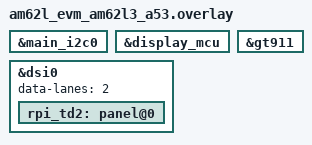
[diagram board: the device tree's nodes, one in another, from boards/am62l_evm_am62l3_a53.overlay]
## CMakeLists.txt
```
# SPDX-FileCopyrightText: 2026 Texas Instruments Incorporated
# SPDX-License-Identifier: LicenseRef-TI-TFL

cmake_minimum_required(VERSION 3.20.0)

find_package(Zephyr REQUIRED HINTS $ENV{ZEPHYR_BASE})
project(ti_smart_home)

set(UI_DIR ${CMAKE_CURRENT_SOURCE_DIR}/ui)

include(${UI_DIR}/file_list_gen.cmake)
include(${UI_DIR}/user_config.cmake)

target_sources(app PRIVATE
    src/main.c
    ${LV_EDITOR_PROJECT_SOURCES}
)

target_include_directories(app PRIVATE ${UI_DIR})

target_compile_definitions(app PRIVATE LV_LVGL_H_INCLUDE_SIMPLE)
```

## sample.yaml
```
sample:
  name: TI Smart Home LVGL UI
  description: >
    Smart Home LVGL UI with Raspberry Pi Touch Display 2 (7", ILI9881C MIPI-DSI
    panel) and GT911 capacitive touch controller.
tests:
  application.ti_smart_home:
    tags:
      - lvgl
      - display
      - gui
    harness: none
    platform_allow:
      - am62l_evm/am62l3/a53
```

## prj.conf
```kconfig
# SPDX-FileCopyrightText: 2026 Texas Instruments Incorporated
# SPDX-License-Identifier: LicenseRef-TI-TFL

CONFIG_DISPLAY=y
CONFIG_LVGL=y
CONFIG_INPUT=y

# ARGB8888 pixel format
CONFIG_LV_COLOR_DEPTH_32=y

# Widgets and features used by the ti-smart-home UI
CONFIG_LV_USE_BAR=y
CONFIG_LV_USE_BUTTON=y
CONFIG_LV_USE_CHART=y
CONFIG_LV_USE_CHECKBOX=y
CONFIG_LV_USE_IMAGE=y
CONFIG_LV_USE_LABEL=y
CONFIG_LV_USE_SLIDER=y
CONFIG_LV_USE_SWITCH=y
CONFIG_LV_USE_OBSERVER=y
CONFIG_LV_USE_OBJ_NAME=y
```

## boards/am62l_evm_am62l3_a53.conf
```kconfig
# SPDX-FileCopyrightText: 2026 Texas Instruments Incorporated
# SPDX-License-Identifier: LicenseRef-TI-TFL

CONFIG_MAIN_STACK_SIZE=12288
CONFIG_LV_Z_MEM_POOL_SIZE=262144
CONFIG_LV_Z_BUFFER_ALLOC_STATIC=y
CONFIG_LV_Z_DOUBLE_VDB=y
CONFIG_LV_Z_FLUSH_THREAD=y
CONFIG_LV_Z_RUN_LVGL_ON_WORKQUEUE=y
CONFIG_LV_Z_DIRECT_RENDERING=y
CONFIG_LV_Z_LVGL_WORKQUEUE_STACK_SIZE=12288
CONFIG_SPEED_OPTIMIZATIONS=y
CONFIG_ILI9881C_DSI_RPI_TOUCH_DISPLAY=y
```

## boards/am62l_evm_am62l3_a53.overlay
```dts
/*
 * SPDX-FileCopyrightText: 2026 Texas Instruments Incorporated
 *
 * SPDX-License-Identifier: LicenseRef-TI-TFL
 */

&main_i2c0 {
	status = "okay";
};

&display_mcu {
	status = "okay";
};

&gt911 {
    status = "okay";
};

&dsi0 {
	data-lanes = <2>;

	rpi_td2: panel@0 {
		status = "okay";
	};
};
```

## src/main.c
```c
/*
 * SPDX-FileCopyrightText: 2026 Texas Instruments Incorporated
 *
 * SPDX-License-Identifier: LicenseRef-TI-TFL
 */

#include <zephyr/kernel.h>
#include <zephyr/drivers/display.h>
#include <lvgl.h>
#include <lvgl_zephyr.h>
#include <ti_smart_home.h>

#define LOG_LEVEL CONFIG_LOG_DEFAULT_LEVEL
#include <zephyr/logging/log.h>
LOG_MODULE_REGISTER(app);

int main(void)
{
	const struct device *display_dev;
	int ret;

	display_dev = DEVICE_DT_GET(DT_CHOSEN(zephyr_display));	
	if (!device_is_ready(display_dev)) {
		LOG_ERR("Display device not ready, aborting");
		return 0;
	}

	lvgl_lock();

	ti_smart_home_init(NULL);

#ifndef CONFIG_LV_Z_RUN_LVGL_ON_WORKQUEUE
	lv_timer_handler();
#endif
	lvgl_unlock();

	ret = display_blanking_off(display_dev);
	if (ret < 0 && ret != -ENOSYS) {
		LOG_ERR("Failed to turn blanking off (error %d)", ret);
		return 0;
	}

	while (1) {
#ifndef CONFIG_LV_Z_RUN_LVGL_ON_WORKQUEUE
		uint32_t sleep_ms;

		lvgl_lock();
		sleep_ms = lv_timer_handler();
		lvgl_unlock();

		k_msleep(MIN(sleep_ms, INT32_MAX));
#else
		/* LVGL is serviced by its dedicated workqueue; just idle here. */
		k_msleep(10);
#endif
	}

	return 0;
}
```
